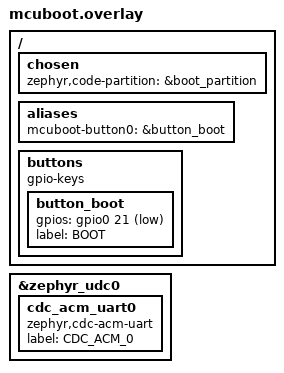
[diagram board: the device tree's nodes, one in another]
/*
 * MCUboot devicetree overlay for RemoteTwo.
 *
 * Ensures USB CDC ACM serial recovery is available and maps boot entry
 * button alias to custom BOOT button on P0.21.
 */

/ {
    chosen {
        zephyr,code-partition = &boot_partition;
    };

    aliases {
        mcuboot-button0 = &button_boot;
    };

    buttons {
        compatible = "gpio-keys";

        button_boot: button_boot {
            gpios = <&gpio0 21 (GPIO_PULL_UP | GPIO_ACTIVE_LOW)>;
            label = "BOOT";
        };
    };
};

&zephyr_udc0 {
    cdc_acm_uart0: cdc_acm_uart0 {
        compatible = "zephyr,cdc-acm-uart";
        label = "CDC_ACM_0";
    };
};
